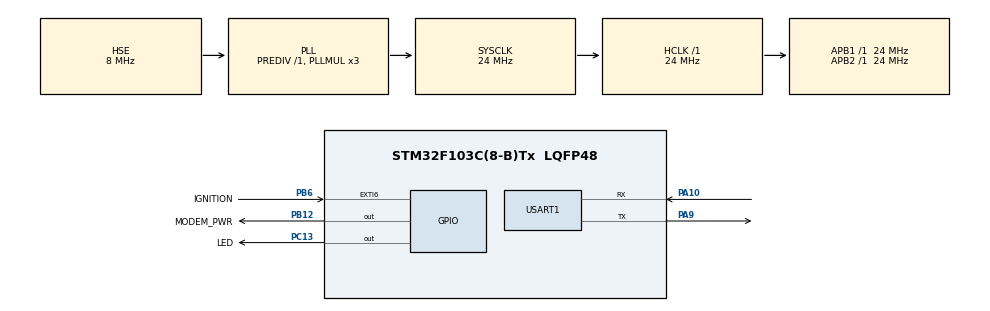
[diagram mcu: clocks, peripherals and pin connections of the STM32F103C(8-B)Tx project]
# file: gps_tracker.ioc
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Dma.Request0=USART1_RX
Dma.USART1_RX.0.Direction=DMA_PERIPH_TO_MEMORY
Dma.USART1_RX.0.Instance=DMA1_Channel5
Dma.USART1_RX.0.MemDataAlignment=DMA_MDATAALIGN_BYTE
Dma.USART1_RX.0.MemInc=DMA_MINC_ENABLE
Dma.USART1_RX.0.Mode=DMA_NORMAL
Dma.USART1_RX.0.PeriphDataAlignment=DMA_PDATAALIGN_BYTE
Dma.USART1_RX.0.PeriphInc=DMA_PINC_DISABLE
Dma.USART1_RX.0.Priority=DMA_PRIORITY_MEDIUM
FREERTOS.Tasks01=trackerTask,24,256,TrackerMainTask,As weak,NULL,Dynamic,NULL,NULL;statusTask,24,256,TrackerStatusTask,As external,NULL,Dynamic,NULL,NULL;checksTask,16,256,PeriodicCheckTask,As external,NULL,Dynamic,NULL,NULL
FREERTOS.configTOTAL_HEAP_SIZE=8000
FREERTOS.configUSE_IDLE_HOOK=1
FREERTOS.configUSE_NEWLIB_REENTRANT=1
FREERTOS.configUSE_TICKLESS_IDLE=1
Mcu.Family=STM32F1
Mcu.Name=STM32F103C(8-B)Tx
Mcu.Package=LQFP48
NVIC.DMA1_Channel5_IRQn=true\:5\:0\:false\:false\:true\:true\:false\:true
NVIC.EXTI9_5_IRQn=true\:5\:0\:false\:false\:true\:true\:true\:true
NVIC.PriorityGroup=NVIC_PRIORITYGROUP_4
NVIC.TIM4_IRQn=true\:15\:0\:true\:false\:true\:false\:false\:true
NVIC.TimeBase=TIM4_IRQn
NVIC.TimeBaseIP=TIM4
NVIC.USART1_IRQn=true\:5\:0\:false\:false\:true\:true\:true\:true
PA10.Mode=Asynchronous
PA10.Signal=USART1_RX
PA13.Mode=Trace_Asynchronous_SW
PA13.Signal=SYS_JTMS-SWDIO
PA14.Mode=Trace_Asynchronous_SW
PA14.Signal=SYS_JTCK-SWCLK
PA9.Mode=Asynchronous
PA9.Signal=USART1_TX
PB12.GPIO_Label=MODEM_PWR
PB12.PinState=GPIO_PIN_SET
PB12.Signal=GPIO_Output
PB3.Mode=Trace_Asynchronous_SW
PB3.Signal=SYS_JTDO-TRACESWO
PB6.GPIO_Label=IGNITION
PB6.GPIO_ModeDefaultEXTI=GPIO_MODE_IT_RISING_FALLING
PB6.GPIO_PuPd=GPIO_PULLDOWN
PB6.Signal=GPXTI6
PC13-TAMPER-RTC.GPIO_Label=LED
PC13-TAMPER-RTC.PinState=GPIO_PIN_SET
PC13-TAMPER-RTC.Signal=GPIO_Output
PC14-OSC32_IN.Mode=LSE-External-Oscillator
PC14-OSC32_IN.Signal=RCC_OSC32_IN
PC15-OSC32_OUT.Mode=LSE-External-Oscillator
PC15-OSC32_OUT.Signal=RCC_OSC32_OUT
PD0-OSC_IN.Mode=HSE-External-Oscillator
PD0-OSC_IN.Signal=RCC_OSC_IN
PD1-OSC_OUT.Mode=HSE-External-Oscillator
PD1-OSC_OUT.Signal=RCC_OSC_OUT
ProjectManager.HeapSize=0x200
ProjectManager.StackSize=0x400
ProjectManager.TargetToolchain=STM32CubeIDE
RCC.AHBFreq_Value=24000000
RCC.APB1Freq_Value=24000000
RCC.APB1TimFreq_Value=24000000
RCC.APB2Freq_Value=24000000
RCC.APB2TimFreq_Value=24000000
RCC.HCLKFreq_Value=24000000
RCC.PLLMUL=RCC_PLL_MUL3
RCC.PLLSourceVirtual=RCC_PLLSOURCE_HSE
RCC.RTCClockSelection=RCC_RTCCLKSOURCE_LSE
RCC.SYSCLKFreq_VALUE=24000000
RCC.SYSCLKSource=RCC_SYSCLKSOURCE_PLLCLK
RCC.USBFreq_Value=24000000
USART1.VirtualMode=VM_ASYNC
VP_FREERTOS_VS_CMSIS_V2.Mode=CMSIS_V2
VP_SYS_VS_tim4.Mode=TIM4
board=custom

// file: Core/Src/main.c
/* USER CODE BEGIN Header */
/**
  ******************************************************************************
  * @file           : main.c
  * @brief          : Main program body
  ******************************************************************************
  * @attention
  *
  * <h2><center>&copy; Copyright (c) 2021 STMicroelectronics.
  * All rights reserved.</center></h2>
  *
  * This software component is licensed by ST under Ultimate Liberty license
  * SLA0044, the "License"; You may not use this file except in compliance with
  * the License. You may obtain a copy of the License at:
  *                             www.st.com/SLA0044
  *
  ******************************************************************************
  */
/* USER CODE END Header */
#include "main.h"
#include "cmsis_os.h"

/* USER CODE BEGIN Includes */
#include "Tracker.h"
/* USER CODE END Includes */

UART_HandleTypeDef huart1;
DMA_HandleTypeDef hdma_usart1_rx;

/* Definitions for trackerTask */
osThreadId_t trackerTaskHandle;
const osThreadAttr_t trackerTask_attributes = {
  .name = "trackerTask",
  .stack_size = 256 * 4,
  .priority = (osPriority_t) osPriorityNormal,
};
/* Definitions for statusTask */
osThreadId_t statusTaskHandle;
const osThreadAttr_t statusTask_attributes = {
  .name = "statusTask",
  .stack_size = 256 * 4,
  .priority = (osPriority_t) osPriorityNormal,
};
/* Definitions for checksTask */
osThreadId_t checksTaskHandle;
const osThreadAttr_t checksTask_attributes = {
  .name = "checksTask",
  .stack_size = 256 * 4,
  .priority = (osPriority_t) osPriorityBelowNormal,
};

void SystemClock_Config(void);
static void MX_GPIO_Init(void);
static void MX_USART1_UART_Init(void);
static void MX_DMA_Init(void);
void TrackerMainTask(void *argument);
extern void TrackerStatusTask(void *argument);
extern void PeriodicCheckTask(void *argument);

/* USER CODE BEGIN 0 */
int __io_putchar(int ch)
{
	ITM_SendChar(ch);
	return ch;
}

/* USER CODE END 0 */

int main(void)
{

  /* MCU Configuration--------------------------------------------------------*/

  /* Reset of all peripherals, Initializes the Flash interface and the Systick. */
  HAL_Init();

  /* Configure the system clock */
  SystemClock_Config();

  /* USER CODE BEGIN SysInit */
  MX_DMA_Init(); // Cube MX bug with DMA+USART
  /* USER CODE END SysInit */

  /* Initialize all configured peripherals */
  MX_GPIO_Init();
  MX_USART1_UART_Init();
  MX_DMA_Init();

  /* Init scheduler */
  osKernelInitialize();

  /* Create the thread(s) */
  /* creation of trackerTask */
  trackerTaskHandle = osThreadNew(TrackerMainTask, NULL, &trackerTask_attributes);

  /* creation of statusTask */
  statusTaskHandle = osThreadNew(TrackerStatusTask, NULL, &statusTask_attributes);

  /* creation of checksTask */
  checksTaskHandle = osThreadNew(PeriodicCheckTask, NULL, &checksTask_attributes);

  /* USER CODE BEGIN RTOS_EVENTS */
  /* add events, ... */
  TrackerInit();
  /* USER CODE END RTOS_EVENTS */

  /* Start scheduler */
  osKernelStart();

  /* We should never get here as control is now taken by the scheduler */
  /* Infinite loop */
  while (1)
  {

  }
}

void SystemClock_Config(void)
{
  RCC_OscInitTypeDef RCC_OscInitStruct = {0};
  RCC_ClkInitTypeDef RCC_ClkInitStruct = {0};

  /** Initializes the RCC Oscillators according to the specified parameters
  * in the RCC_OscInitTypeDef structure.
  */
  RCC_OscInitStruct.OscillatorType = RCC_OSCILLATORTYPE_HSE;
  RCC_OscInitStruct.HSEState = RCC_HSE_ON;
  RCC_OscInitStruct.HSEPredivValue = RCC_HSE_PREDIV_DIV1;
  RCC_OscInitStruct.HSIState = RCC_HSI_ON;
  RCC_OscInitStruct.PLL.PLLState = RCC_PLL_ON;
  RCC_OscInitStruct.PLL.PLLSource = RCC_PLLSOURCE_HSE;
  RCC_OscInitStruct.PLL.PLLMUL = RCC_PLL_MUL3;
  if (HAL_RCC_OscConfig(&RCC_OscInitStruct) != HAL_OK)
  {
    Error_Handler();
  }
  /** Initializes the CPU, AHB and APB buses clocks
  */
  RCC_ClkInitStruct.ClockType = RCC_CLOCKTYPE_HCLK|RCC_CLOCKTYPE_SYSCLK
                              |RCC_CLOCKTYPE_PCLK1|RCC_CLOCKTYPE_PCLK2;
  RCC_ClkInitStruct.SYSCLKSource = RCC_SYSCLKSOURCE_PLLCLK;
  RCC_ClkInitStruct.AHBCLKDivider = RCC_SYSCLK_DIV1;
  RCC_ClkInitStruct.APB1CLKDivider = RCC_HCLK_DIV1;
  RCC_ClkInitStruct.APB2CLKDivider = RCC_HCLK_DIV1;

  if (HAL_RCC_ClockConfig(&RCC_ClkInitStruct, FLASH_LATENCY_0) != HAL_OK)
  {
    Error_Handler();
  }
}

static void MX_USART1_UART_Init(void)
{

  huart1.Instance = USART1;
  huart1.Init.BaudRate = 115200;
  huart1.Init.WordLength = UART_WORDLENGTH_8B;
  huart1.Init.StopBits = UART_STOPBITS_1;
  huart1.Init.Parity = UART_PARITY_NONE;
  huart1.Init.Mode = UART_MODE_TX_RX;
  huart1.Init.HwFlowCtl = UART_HWCONTROL_NONE;
  huart1.Init.OverSampling = UART_OVERSAMPLING_16;
  if (HAL_UART_Init(&huart1) != HAL_OK)
  {
    Error_Handler();
  }

}

static void MX_DMA_Init(void)
{

  /* DMA controller clock enable */
  __HAL_RCC_DMA1_CLK_ENABLE();

  /* DMA interrupt init */
  /* DMA1_Channel5_IRQn interrupt configuration */
  HAL_NVIC_SetPriority(DMA1_Channel5_IRQn, 5, 0);
  HAL_NVIC_EnableIRQ(DMA1_Channel5_IRQn);

}

static void MX_GPIO_Init(void)
{
  GPIO_InitTypeDef GPIO_InitStruct = {0};

  /* GPIO Ports Clock Enable */
  __HAL_RCC_GPIOC_CLK_ENABLE();
  __HAL_RCC_GPIOD_CLK_ENABLE();
  __HAL_RCC_GPIOB_CLK_ENABLE();
  __HAL_RCC_GPIOA_CLK_ENABLE();

  /*Configure GPIO pin Output Level */
  HAL_GPIO_WritePin(LED_GPIO_Port, LED_Pin, GPIO_PIN_SET);

  /*Configure GPIO pin Output Level */
  HAL_GPIO_WritePin(MODEM_PWR_GPIO_Port, MODEM_PWR_Pin, GPIO_PIN_SET);

  /*Configure GPIO pin : LED_Pin */
  GPIO_InitStruct.Pin = LED_Pin;
  GPIO_InitStruct.Mode = GPIO_MODE_OUTPUT_PP;
  GPIO_InitStruct.Pull = GPIO_NOPULL;
  GPIO_InitStruct.Speed = GPIO_SPEED_FREQ_LOW;
  HAL_GPIO_Init(LED_GPIO_Port, &GPIO_InitStruct);

  /*Configure GPIO pin : MODEM_PWR_Pin */
  GPIO_InitStruct.Pin = MODEM_PWR_Pin;
  GPIO_InitStruct.Mode = GPIO_MODE_OUTPUT_PP;
  GPIO_InitStruct.Pull = GPIO_NOPULL;
  GPIO_InitStruct.Speed = GPIO_SPEED_FREQ_LOW;
  HAL_GPIO_Init(MODEM_PWR_GPIO_Port, &GPIO_InitStruct);

  /*Configure GPIO pin : IGNITION_Pin */
  GPIO_InitStruct.Pin = IGNITION_Pin;
  GPIO_InitStruct.Mode = GPIO_MODE_IT_RISING_FALLING;
  GPIO_InitStruct.Pull = GPIO_PULLDOWN;
  HAL_GPIO_Init(IGNITION_GPIO_Port, &GPIO_InitStruct);

  /* EXTI interrupt init*/
  HAL_NVIC_SetPriority(EXTI9_5_IRQn, 5, 0);
  HAL_NVIC_EnableIRQ(EXTI9_5_IRQn);

}

/* USER CODE BEGIN 4 */
void PreSleepProcessing(uint32_t *ulExpectedIdleTime)
{
	HAL_SuspendTick();
}

void PostSleepProcessing(uint32_t *ulExpectedIdleTime)
{
	HAL_ResumeTick();
}

/* USER CODE END 4 */

__weak void TrackerMainTask(void *argument)
{
  /* USER CODE BEGIN 5 */
  /* Infinite loop */
  for(;;)
  {
    osDelay(500);
  }
  /* USER CODE END 5 */
}

void HAL_TIM_PeriodElapsedCallback(TIM_HandleTypeDef *htim)
{
  if (htim->Instance == TIM4) {
    HAL_IncTick();
  }
}

void Error_Handler(void)
{
  __disable_irq();
  while (1)
  {
  }
}

/************************ (C) COPYRIGHT STMicroelectronics *****END OF FILE****/

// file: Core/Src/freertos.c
/* USER CODE BEGIN Header */
/**
  ******************************************************************************
  * File Name          : freertos.c
  * Description        : Code for freertos applications
  ******************************************************************************
  * @attention
  *
  * <h2><center>&copy; Copyright (c) 2021 STMicroelectronics.
  * All rights reserved.</center></h2>
  *
  * This software component is licensed by ST under Ultimate Liberty license
  * SLA0044, the "License"; You may not use this file except in compliance with
  * the License. You may obtain a copy of the License at:
  *                             www.st.com/SLA0044
  *
  ******************************************************************************
  */
/* USER CODE END Header */

#include "FreeRTOS.h"
#include "task.h"
#include "main.h"

/* Hook prototypes */
void vApplicationIdleHook(void);

/* USER CODE BEGIN 2 */
void vApplicationIdleHook( void )
{
   /* vApplicationIdleHook() will only be called if configUSE_IDLE_HOOK is set
   to 1 in FreeRTOSConfig.h. It will be called on each iteration of the idle
   task. It is essential that code added to this hook function never attempts
   to block in any way (for example, call xQueueReceive() with a block time
   specified, or call vTaskDelay()). If the application makes use of the
   vTaskDelete() API function (as this demo application does) then it is also
   important that vApplicationIdleHook() is permitted to return to its calling
   function, because it is the responsibility of the idle task to clean up
   memory allocated by the kernel to any task that has since been deleted. */
    HAL_SuspendTick();
    HAL_PWR_EnterSLEEPMode(PWR_MAINREGULATOR_ON, PWR_SLEEPENTRY_WFI);
    HAL_ResumeTick();
}
/* USER CODE END 2 */

/* USER CODE BEGIN PREPOSTSLEEP */
__weak void PreSleepProcessing(uint32_t *ulExpectedIdleTime)
{
/* place for user code */
}

__weak void PostSleepProcessing(uint32_t *ulExpectedIdleTime)
{
/* place for user code */
}
/* USER CODE END PREPOSTSLEEP */

/************************ (C) COPYRIGHT STMicroelectronics *****END OF FILE****/
